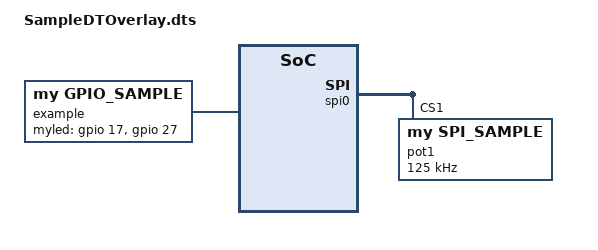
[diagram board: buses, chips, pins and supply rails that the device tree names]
/dts-v1/;
/plugin/;

/ {
	fragment@0 {
    	target-path = "/";
        __overlay__ {
        	mine_led: led-mine {
        		compatible = "my,gpio_sample";
        		label = "example";
        		myled-gpios = <&gpio 17 0>,	/* Red   LED */
					<&gpio 27 0>;	/* Green LED */
			  	status = "okay";
        		};
		};
	};
	
	fragment@1 {
        target = <&spi0>;
        __overlay__ {
        	/* needed to avoid dtc warning */
            	#address-cells = <1>;
            	#size-cells = <0>;
		status = "okay";
		pot1: mcp4132@1 {
			reg = <1>;
                	compatible = "my,spi_sample";
			spi-max-frequency = <125000>;
			};
		};
	};
};
